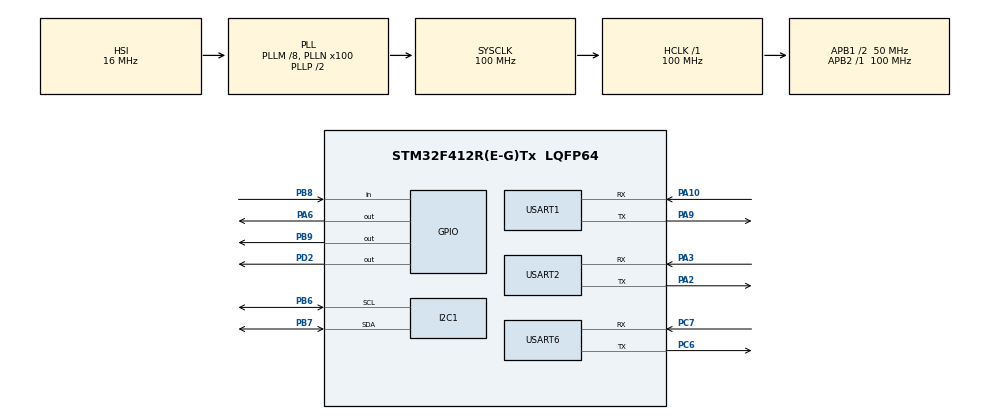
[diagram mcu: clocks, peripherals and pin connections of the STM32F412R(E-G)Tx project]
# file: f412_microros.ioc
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Dma.Request0=USART2_RX
Dma.Request1=USART2_TX
Dma.Request2=USART1_RX
Dma.Request3=USART1_TX
Dma.Request4=USART6_RX
Dma.Request5=USART6_TX
Dma.USART1_RX.2.Direction=DMA_PERIPH_TO_MEMORY
Dma.USART1_RX.2.FIFOMode=DMA_FIFOMODE_DISABLE
Dma.USART1_RX.2.Instance=DMA2_Stream2
Dma.USART1_RX.2.MemDataAlignment=DMA_MDATAALIGN_BYTE
Dma.USART1_RX.2.MemInc=DMA_MINC_ENABLE
Dma.USART1_RX.2.Mode=DMA_NORMAL
Dma.USART1_RX.2.PeriphDataAlignment=DMA_PDATAALIGN_BYTE
Dma.USART1_RX.2.PeriphInc=DMA_PINC_DISABLE
Dma.USART1_RX.2.Priority=DMA_PRIORITY_LOW
Dma.USART1_TX.3.Direction=DMA_MEMORY_TO_PERIPH
Dma.USART1_TX.3.FIFOMode=DMA_FIFOMODE_DISABLE
Dma.USART1_TX.3.Instance=DMA2_Stream7
Dma.USART1_TX.3.MemDataAlignment=DMA_MDATAALIGN_BYTE
Dma.USART1_TX.3.MemInc=DMA_MINC_ENABLE
Dma.USART1_TX.3.Mode=DMA_NORMAL
Dma.USART1_TX.3.PeriphDataAlignment=DMA_PDATAALIGN_BYTE
Dma.USART1_TX.3.PeriphInc=DMA_PINC_DISABLE
Dma.USART1_TX.3.Priority=DMA_PRIORITY_LOW
Dma.USART2_RX.0.Direction=DMA_PERIPH_TO_MEMORY
Dma.USART2_RX.0.FIFOMode=DMA_FIFOMODE_DISABLE
Dma.USART2_RX.0.Instance=DMA1_Stream5
Dma.USART2_RX.0.MemDataAlignment=DMA_MDATAALIGN_BYTE
Dma.USART2_RX.0.MemInc=DMA_MINC_ENABLE
Dma.USART2_RX.0.Mode=DMA_CIRCULAR
Dma.USART2_RX.0.PeriphDataAlignment=DMA_PDATAALIGN_BYTE
Dma.USART2_RX.0.PeriphInc=DMA_PINC_DISABLE
Dma.USART2_RX.0.Priority=DMA_PRIORITY_VERY_HIGH
Dma.USART2_TX.1.Direction=DMA_MEMORY_TO_PERIPH
Dma.USART2_TX.1.FIFOMode=DMA_FIFOMODE_DISABLE
Dma.USART2_TX.1.Instance=DMA1_Stream6
Dma.USART2_TX.1.MemDataAlignment=DMA_MDATAALIGN_BYTE
Dma.USART2_TX.1.MemInc=DMA_MINC_ENABLE
Dma.USART2_TX.1.Mode=DMA_NORMAL
Dma.USART2_TX.1.PeriphDataAlignment=DMA_PDATAALIGN_BYTE
Dma.USART2_TX.1.PeriphInc=DMA_PINC_DISABLE
Dma.USART2_TX.1.Priority=DMA_PRIORITY_VERY_HIGH
Dma.USART6_RX.4.Direction=DMA_PERIPH_TO_MEMORY
Dma.USART6_RX.4.FIFOMode=DMA_FIFOMODE_DISABLE
Dma.USART6_RX.4.Instance=DMA2_Stream1
Dma.USART6_RX.4.MemDataAlignment=DMA_MDATAALIGN_BYTE
Dma.USART6_RX.4.MemInc=DMA_MINC_ENABLE
Dma.USART6_RX.4.Mode=DMA_NORMAL
Dma.USART6_RX.4.PeriphDataAlignment=DMA_PDATAALIGN_BYTE
Dma.USART6_RX.4.PeriphInc=DMA_PINC_DISABLE
Dma.USART6_RX.4.Priority=DMA_PRIORITY_LOW
Dma.USART6_TX.5.Direction=DMA_MEMORY_TO_PERIPH
Dma.USART6_TX.5.FIFOMode=DMA_FIFOMODE_DISABLE
Dma.USART6_TX.5.Instance=DMA2_Stream6
Dma.USART6_TX.5.MemDataAlignment=DMA_MDATAALIGN_BYTE
Dma.USART6_TX.5.MemInc=DMA_MINC_ENABLE
Dma.USART6_TX.5.Mode=DMA_NORMAL
Dma.USART6_TX.5.PeriphDataAlignment=DMA_PDATAALIGN_BYTE
Dma.USART6_TX.5.PeriphInc=DMA_PINC_DISABLE
Dma.USART6_TX.5.Priority=DMA_PRIORITY_LOW
FREERTOS.Tasks01=defaultTask,24,3000,StartDefaultTask,Default,NULL,Static,defaultTaskBuffer,defaultTaskControlBlock
Mcu.Family=STM32F4
Mcu.Name=STM32F412R(E-G)Tx
Mcu.Package=LQFP64
NVIC.DMA1_Stream5_IRQn=true\:5\:0\:false\:false\:true\:true\:false\:true\:true
NVIC.DMA1_Stream6_IRQn=true\:5\:0\:false\:false\:true\:true\:false\:true\:true
NVIC.DMA2_Stream1_IRQn=true\:5\:0\:false\:false\:true\:true\:false\:true\:true
NVIC.DMA2_Stream2_IRQn=true\:5\:0\:false\:false\:true\:true\:false\:true\:true
NVIC.DMA2_Stream6_IRQn=true\:5\:0\:false\:false\:true\:true\:false\:true\:true
NVIC.DMA2_Stream7_IRQn=true\:5\:0\:false\:false\:true\:true\:false\:true\:true
NVIC.PriorityGroup=NVIC_PRIORITYGROUP_4
NVIC.TIM1_UP_TIM10_IRQn=true\:15\:0\:false\:false\:true\:false\:false\:true\:true
NVIC.TimeBase=TIM1_UP_TIM10_IRQn
NVIC.TimeBaseIP=TIM1
NVIC.USART1_IRQn=true\:5\:0\:false\:false\:true\:true\:true\:true\:true
NVIC.USART2_IRQn=true\:5\:0\:false\:false\:true\:true\:true\:true\:true
NVIC.USART6_IRQn=true\:5\:0\:false\:false\:true\:true\:true\:true\:true
PA10.Mode=Asynchronous
PA10.Signal=USART1_RX
PA2.Mode=Asynchronous
PA2.Signal=USART2_TX
PA3.Mode=Asynchronous
PA3.Signal=USART2_RX
PA6.Signal=GPIO_Output
PA9.Mode=Asynchronous
PA9.Signal=USART1_TX
PB6.Mode=I2C
PB6.Signal=I2C1_SCL
PB7.Mode=I2C
PB7.Signal=I2C1_SDA
PB8.Signal=GPIO_Input
PB9.Signal=GPIO_Output
PC6.Mode=Asynchronous
PC6.Signal=USART6_TX
PC7.Mode=Asynchronous
PC7.Signal=USART6_RX
PD2.Signal=GPIO_Output
PH0\ -\ OSC_IN.Mode=HSE-External-Oscillator
PH0\ -\ OSC_IN.Signal=RCC_OSC_IN
PH1\ -\ OSC_OUT.Mode=HSE-External-Oscillator
PH1\ -\ OSC_OUT.Signal=RCC_OSC_OUT
ProjectManager.HeapSize=0x200
ProjectManager.StackSize=0x400
ProjectManager.TargetToolchain=Makefile
RCC.AHBFreq_Value=100000000
RCC.APB1CLKDivider=RCC_HCLK_DIV2
RCC.APB1Freq_Value=50000000
RCC.APB1TimFreq_Value=100000000
RCC.APB2Freq_Value=100000000
RCC.APB2TimFreq_Value=100000000
RCC.CortexFreq_Value=100000000
RCC.HCLKFreq_Value=100000000
RCC.PLLM=8
RCC.PLLN=100
RCC.SYSCLKFreq_VALUE=100000000
RCC.SYSCLKSource=RCC_SYSCLKSOURCE_PLLCLK
RCC.USBFreq_Value=100000000
RCC.VCOOutputFreq_Value=200000000
TIM3.Prescaler=99
USART1.VirtualMode=VM_ASYNC
USART2.VirtualMode=VM_ASYNC
USART6.VirtualMode=VM_ASYNC
VP_FREERTOS_VS_CMSIS_V2.Mode=CMSIS_V2
VP_SYS_VS_tim1.Mode=TIM1
VP_TIM3_VS_ClockSourceINT.Mode=Internal
board=custom

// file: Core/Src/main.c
/* USER CODE BEGIN Header */
/**
  ******************************************************************************
  * @file           : main.c
  * @brief          : Main program body
  ******************************************************************************
  * @attention
  *
  * Copyright (c) 2025 STMicroelectronics.
  * All rights reserved.
  *
  * This software is licensed under terms that can be found in the LICENSE file
  * in the root directory of this software component.
  * If no LICENSE file comes with this software, it is provided AS-IS.
  *
  ******************************************************************************
  */
/* USER CODE END Header */
#include "main.h"
#include "cmsis_os.h"
#include "dma.h"
#include "i2c.h"
#include "tim.h"
#include "usart.h"
#include "gpio.h"

/* USER CODE BEGIN Includes */
#include "app_main.h"
/* USER CODE END Includes */

void SystemClock_Config(void);
void MX_FREERTOS_Init(void);

int main(void)
{

  /* USER CODE BEGIN 1 */
	 App_Main_Init();
  /* USER CODE END 1 */

  /* MCU Configuration--------------------------------------------------------*/

  /* Reset of all peripherals, Initializes the Flash interface and the Systick. */
  HAL_Init();

  /* USER CODE BEGIN Init */
  //App_Main_Init();
  /* USER CODE END Init */

  /* Configure the system clock */
  SystemClock_Config();

  /* Initialize all configured peripherals */
  MX_GPIO_Init();
  MX_DMA_Init();
  MX_USART2_UART_Init();
  MX_TIM3_Init();
  MX_USART1_UART_Init();
  MX_USART6_UART_Init();
  MX_I2C1_Init();

  /* Init scheduler */
  osKernelInitialize();  /* Call init function for freertos objects (in cmsis_os2.c) */
  MX_FREERTOS_Init();

  /* Start scheduler */
  osKernelStart();

  /* We should never get here as control is now taken by the scheduler */

  /* Infinite loop */
  while (1)
  {

  }
}

void SystemClock_Config(void)
{
  RCC_OscInitTypeDef RCC_OscInitStruct = {0};
  RCC_ClkInitTypeDef RCC_ClkInitStruct = {0};

  /** Configure the main internal regulator output voltage
  */
  __HAL_RCC_PWR_CLK_ENABLE();
  __HAL_PWR_VOLTAGESCALING_CONFIG(PWR_REGULATOR_VOLTAGE_SCALE1);

  /** Initializes the RCC Oscillators according to the specified parameters
  * in the RCC_OscInitTypeDef structure.
  */
  RCC_OscInitStruct.OscillatorType = RCC_OSCILLATORTYPE_HSI;
  RCC_OscInitStruct.HSIState = RCC_HSI_ON;
  RCC_OscInitStruct.HSICalibrationValue = RCC_HSICALIBRATION_DEFAULT;
  RCC_OscInitStruct.PLL.PLLState = RCC_PLL_ON;
  RCC_OscInitStruct.PLL.PLLSource = RCC_PLLSOURCE_HSI;
  RCC_OscInitStruct.PLL.PLLM = 8;
  RCC_OscInitStruct.PLL.PLLN = 100;
  RCC_OscInitStruct.PLL.PLLP = RCC_PLLP_DIV2;
  RCC_OscInitStruct.PLL.PLLQ = 2;
  RCC_OscInitStruct.PLL.PLLR = 2;
  if (HAL_RCC_OscConfig(&RCC_OscInitStruct) != HAL_OK)
  {
    Error_Handler();
  }

  /** Initializes the CPU, AHB and APB buses clocks
  */
  RCC_ClkInitStruct.ClockType = RCC_CLOCKTYPE_HCLK|RCC_CLOCKTYPE_SYSCLK
                              |RCC_CLOCKTYPE_PCLK1|RCC_CLOCKTYPE_PCLK2;
  RCC_ClkInitStruct.SYSCLKSource = RCC_SYSCLKSOURCE_PLLCLK;
  RCC_ClkInitStruct.AHBCLKDivider = RCC_SYSCLK_DIV1;
  RCC_ClkInitStruct.APB1CLKDivider = RCC_HCLK_DIV2;
  RCC_ClkInitStruct.APB2CLKDivider = RCC_HCLK_DIV1;

  if (HAL_RCC_ClockConfig(&RCC_ClkInitStruct, FLASH_LATENCY_3) != HAL_OK)
  {
    Error_Handler();
  }
}

void HAL_TIM_PeriodElapsedCallback(TIM_HandleTypeDef *htim)
{
  if (htim->Instance == TIM1)
  {
    HAL_IncTick();
  }
}

void Error_Handler(void)
{
  __disable_irq();
  while (1)
  {
  }
}

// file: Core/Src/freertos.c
/* USER CODE BEGIN Header */
/**
  ******************************************************************************
  * File Name          : freertos.c
  * Description        : Code for freertos applications
  ******************************************************************************
  * @attention
  *
  * Copyright (c) 2025 STMicroelectronics.
  * All rights reserved.
  *
  * This software is licensed under terms that can be found in the LICENSE file
  * in the root directory of this software component.
  * If no LICENSE file comes with this software, it is provided AS-IS.
  *
  ******************************************************************************
  */
/* USER CODE END Header */

#include "FreeRTOS.h"
#include "task.h"
#include "main.h"
#include "cmsis_os.h"

typedef StaticTask_t osStaticThreadDef_t;

/* Definitions for defaultTask */
osThreadId_t defaultTaskHandle;
uint32_t defaultTaskBuffer[ 3000 ];
osStaticThreadDef_t defaultTaskControlBlock;
const osThreadAttr_t defaultTask_attributes = {
  .name = "defaultTask",
  .cb_mem = &defaultTaskControlBlock,
  .cb_size = sizeof(defaultTaskControlBlock),
  .stack_mem = &defaultTaskBuffer[0],
  .stack_size = sizeof(defaultTaskBuffer),
  .priority = (osPriority_t) osPriorityNormal,
};

void StartDefaultTask(void *argument);

void MX_FREERTOS_Init(void); /* (MISRA C 2004 rule 8.1) */

void MX_FREERTOS_Init(void) {

  /* Create the thread(s) */
  /* creation of defaultTask */
  defaultTaskHandle = osThreadNew(StartDefaultTask, NULL, &defaultTask_attributes);

}

void StartDefaultTask(void *argument)
{
  for(;;)
  {
    osDelay(1);
  }
}
